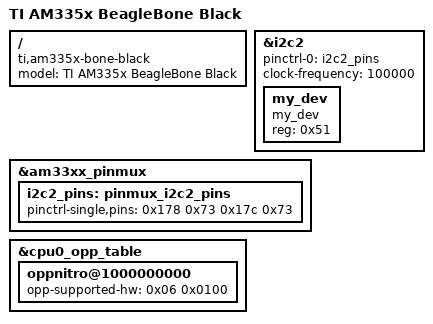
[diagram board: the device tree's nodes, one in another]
/*
 * Copyright (C) 2012 Texas Instruments Incorporated - http://www.ti.com/
 *
 * This program is free software; you can redistribute it and/or modify
 * it under the terms of the GNU General Public License version 2 as
 * published by the Free Software Foundation.
 */
/dts-v1/;

#include "am33xx.dtsi"
#include "am335x-bone-common.dtsi"
#include "am335x-boneblack-common.dtsi"
/* #include "am335x-bone-jtag.dtsi" */

/ {
	model = "TI AM335x BeagleBone Black";
	compatible = "ti,am335x-bone-black", "ti,am335x-bone", "ti,am33xx";


};


&i2c2 {
    pinctrl-names = "default";
    pinctrl-0 = <&i2c2_pins>;
    status = "okay";
    clock-frequency = <100000>;

    #address-cells = <1>;
    #size-cells = <0>;

    /*
     *   Node for my_dev
     *   Moved from root to i2c node as a child node.
     */
    my_dev{

	compatible = "my_dev";
	reg = <0x51>;
	
	   
		


    };
};    



&am33xx_pinmux{
	i2c2_pins: pinmux_i2c2_pins {
		   pinctrl-single,pins = <
			   0x178 0x73  
			   0x17c 0x73
		   >;
	};
};

&cpu0_opp_table {
	/*
	 * All PG 2.0 silicon may not support 1GHz but some of the early
	 * BeagleBone Blacks have PG 2.0 silicon which is guaranteed
	 * to support 1GHz OPP so enable it for PG 2.0 on this board.
	 */
	oppnitro@1000000000 {
		opp-supported-hw = <0x06 0x0100>;
	};
};
